# RSL15 register map
Vendor: ONSemiconductor; Series: RSL15 Series; File version: 1.0
CPU: CM33 r0p4, little endian, MPU, FPU, 3 interrupt priority bits
Registers are 32-bit, read-write, reset 0x0 unless marked. A register's access mark holds for its fields unless they carry their own. Offsets are from the block's base; [hi:lo] are bit positions; {n}, {i} and the like mark numbered series; 'fields as' and 'values as' point back to an identical list.

## BB — Baseband Controller
Base 0x40001900
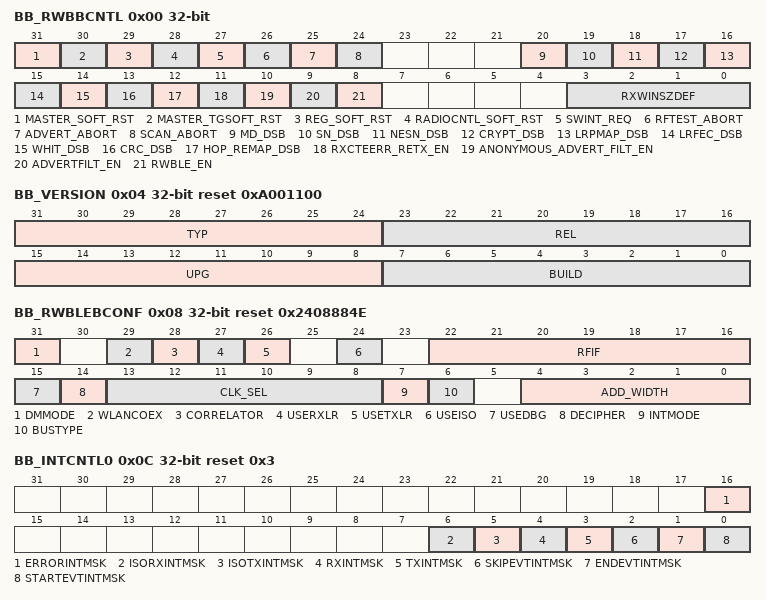
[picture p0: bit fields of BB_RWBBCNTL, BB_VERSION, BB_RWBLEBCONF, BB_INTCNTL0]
0x00 BB_RWBBCNTL — Baseband control register
  [31] MASTER_SOFT_RST — Reset the complete system except registers and timing generator
    0=No action happens if it is written with 0; 1=Resets the complete system at 0
  [30] MASTER_TGSOFT_RST — Reset the timing generator
    0=No action happens if it is written with 0; 1=Resets the timing generator at 0
  [29] REG_SOFT_RST — Reset the complete register block
    0=No action happens if it is written with 0; 1=Resets the complete register block at 0
  [28] RADIOCNTL_SOFT_RST — Reset the radio controller
    0=No action happens if it is written with 0; 1=Reset the radio controller, when written with a 1
  [27] SWINT_REQ — Force the generation of ble_sw_irq
    0=No action happens if it is written with 0; 1=When written with a 1 and proper masking is set, resets at 0
  [26] RFTEST_ABORT — Abort the current RF testing defined as per CS-FORMAT
    0=No action happens if it is written with 0; 1=Abort the current RF testing
  [25] ADVERT_ABORT — Abort the current scan window
    0=No action happens if it is written with 0; 1=Abort the current scan window
  [24] SCAN_ABORT — Abort the current advertising event
    0=No action happens if it is written with 0; 1=Abort the current advertising event
  [20] MD_DSB — Allow a single Tx/Rx exchange whatever the MD bits are
    0=Normal operation of MD bits management; 1=Allow a single Tx/Rx exchange whatever the MD bits are
  [19] SN_DSB — Disable sequence number management
    0=Normal operation of sequence number; 1=Sequence number management disabled
  [18] NESN_DSB — Disable acknowledge scheme
    0=Normal operation of acknowledge; 1=Acknowledge scheme disabled
  [17] CRYPT_DSB — Disable encryption/decryption
    0=Normal operation (encryption / decryption enabled); 1=Encryption / decryption disabled
  [16] LRPMAP_DSB — LR pattern mapper/demapper enabled (has effect only if RW_BLE_LONG_RANGE_INST is defined)
    0=Normal operation. LR Pattern Mapper/Demapper enabled; 1=LR Pattern Mapper/Demapper disabled
  [15] LRFEC_DSB — LR FEC encoder/decoder enabled (has effect only if RW_BLE_LONG_RANGE_INST is defined)
    0=Normal operation. LR FEC encoder/decoder enabled; 1=LR FEC encoder/decoder disabled
  [14] WHIT_DSB — Disable whitening
    0=Normal operation (whitening enabled); 1=Whitening disabled
  [13] CRC_DSB — Disable CRC stripping
    0=Normal operation (CRC removed from data stream); 1=CRC stripping disabled on Rx packets, CRC replaced by 0x000 in Tx
  [12] HOP_REMAP_DSB — Disable frequency hopping remapping algorithm
    0=Normal operation (requency hopping remapping algorithm enabled); 1=Frequency hopping remapping algorithm disabled
  [11] RXCTEERR_RETX_EN — Rx CTE error detection
    0=RX_CTE_ERROR_DETECTION_0 (RW-BLE Core does not reports anonymous advertiser to RW-BLE Software); 1=RX_CTE_ERROR_DETECTION_1 (RW-BLE Core reports anonymous advertisers to RW-BLE Software)
  [10] ANONYMOUS_ADVERT_FILT_EN — Anonymous extended advertising filtering enable control (operate in extended active scanner and extended passive scanner modes only, and when white list is used by device filtering policy)
    0=RW-BLE Core does not reports anonymous advertiser to RW-BLE Software; 1=RW-BLE Core reports anonymous advertisers to RW-BLE Software
  [9] ADVERTFILT_EN — Advertising channels error filtering enable control
    0=RW-BLE core reports all errors to RW-BLE software; 1=RW-BLE core reports only correctly received packet, without error to RW-BLE software
  [8] RWBLE_EN — Enable RW-BLE core exchange table pre-fetch mechanism
    0=Disable RW-BLE core exchange table pre-fetch mechanism; 1=Enable RW-BLE core exchange table pre-fetch mechanism
  [3:0] RXWINSZDEF — Default Rx window size in us (used when device is master connected or performs its second receipt)
    0=Default Rx half Window size in us for uncoded PHY, and in multiple of 2us for coded PHY
0x04 BB_VERSION ro reset 0xA001100 — BLE revision register
  [31:24] TYP — RW-BLE core type
    10=TYP_A (BLE v5.1 Madrid release)
  [23:16] REL — RW-BLE core version - major release number
  [15:8] UPG — RW-BLE core upgrade - upgrade number
    17=UPG_11
  [7:0] BUILD — RW-BLE core build - build number
0x08 BB_RWBLEBCONF ro reset 0x2408884E — Baseband configuration register (compilation options dependant)
  [31] DMMODE — RW-BLE core dual mode
    0=RW-BLE core is used as a standalone BLE device; 1=RW-BLE core is used in a dual mode device
  [29] WLANCOEX — WLAN coexistence mechanism
    0=COEX_0 (WLAN coexistence mechanism not present); 1=COEX_1 (WLAN coexistence mechanism present)
  [28] CORRELATOR — Correlator present
    0=Correlator logic is not present; 1=Correlator logic is present
  [27] USERXLR — Long range Rx present
    0=Long Range receive bit-stream logic is not present; 1=Long Range receive bit-stream logic is present
  [26] USETXLR — Long range Tx present
    0=Long Range transmit bit-stream logic is not present; 1=Long Range transmit bit-stream logic is present
  [24] USEISO — Support of isochronous channels
    0=Isochronous channel feature not supported; 1=Isochronous channel feature supported
  [22:16] RFIF — Support of the RF front-end
    1=RFIF_RIPPLE (Ripple and Thesis RF); 2=RFIF_EXT (External radio controller support); 4=RFIFCALYPSO (Calypso radio); 8=RFIF_ICYTRX_V2 (IcyTRx version 2 radio); 16=RFIF_BTIPT (BTIPT radio); 32=RFIF_AURA_SEMI (Aura semi 50xx radio); 64=RFIF_RESERVED (Reserved)
  [15] USEDBG — Diagnostic port
    0=WLAN coexistence mechanism present; 1=Diagnostic port instantiated
  [14] DECIPHER — AES deciphering present
    0=AES deciphering not present; 1=AES deciphering present
  [13:8] CLK_SEL — Operating frequency (in MHz)
    8=Default value is 8MHz
  [7] INTMODE — Interruption mode
    0=Interrupts are edge level generated, i.e. pulse; 1=Interrupts are trigger level generated, i.e. stays active at 1 till acknowledgement
  [6] BUSTYPE — Processor bus type
    0=Processor bus type: AHB bus; 1=Processor bus type: XBAR bus
  [4:0] ADD_WIDTH — Value of the RW_BLE_ADDRESS_WIDTH parameter concerted into binary
    14=EM size is 16kB
0x0C BB_INTCNTL0 reset 0x3 — Interrupts control register 0
  [16] ERRORINTMSK — Error interrupt mask
    0=Interrupt not generated; 1=Interrupt generated
  [6] ISORXINTMSK — Isochronous channel Rx interrupt mask
    0=Interrupt not reported in FIFO IRQ; 1=Interrupt reported in FIFO IRQ
  [5] ISOTXINTMSK — Isochronous channel Tx interrupt mask
    values as ISORXINTMSK
  [4] RXINTMSK — Rx interrupt mask
    values as ISORXINTMSK
  [3] TXINTMSK — Tx interrupt mask
    values as ISORXINTMSK
  [2] SKIPEVTINTMSK — Skipped event interrupt mask
    values as ISORXINTMSK
  [1] ENDEVTINTMSK — End of event interrupt mask
    values as ISORXINTMSK
  [0] STARTEVTINTMSK — Start of event interrupt mask
    values as ISORXINTMSK
0x10 BB_INTSTAT0 ro — Interrupts status register 0
  [16] ERRORINTSTAT — Error interrupt status
    0=No error interrupt; 1=An error interrupt is pending
0x14 BB_INTACK0 — Interrupts raw status register 0
  [16] ERRORINTACK — Error interrupt acknowledgement
    0=No error interrupt; 1=An error interrupt is pending
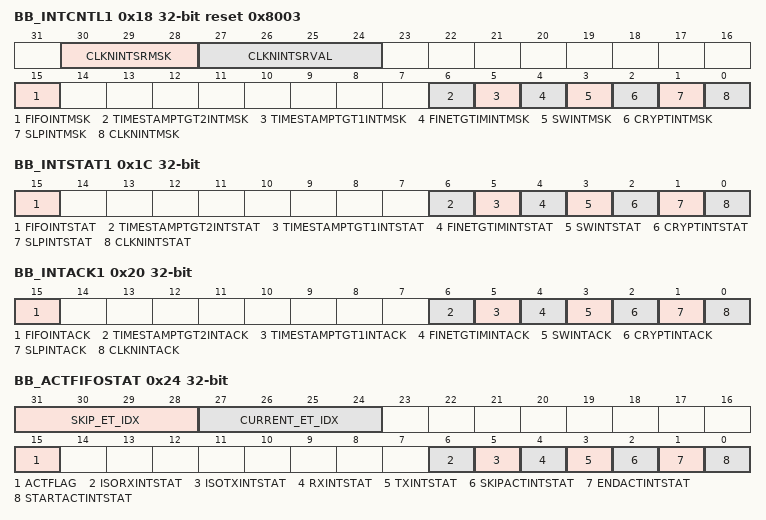
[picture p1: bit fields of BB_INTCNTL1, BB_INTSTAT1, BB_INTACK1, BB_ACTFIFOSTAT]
0x18 BB_INTCNTL1 reset 0x8003 — Interrupts control register 1
  [30:28] CLKNINTSRMSK — CLKN/half-slot interrupt sub rating mask (valid range is [0:4])
  [27:24] CLKNINTSRVAL — CLKN/half-slot interrupt sub rating value
  [15] FIFOINTMSK — FIFO interrupt mask
    0=Interrupt not generated; 1=Interrupt generated
  [6] TIMESTAMPTGT2INTMSK — Time stamp target timer 2 interrupt mask
    0=Interrupt not generated; 1=Interrupt generated
  [5] TIMESTAMPTGT1INTMSK — Time stamp target timer 1 interrupt mask
    0=Interrupt not generated; 1=Interrupt generated
  [4] FINETGTIMINTMSK — Fine target timer interrupt mask
    0=Interrupt not generated; 1=Interrupt generated
  [3] SWINTMSK — SW triggered interrupt mask
    0=Interrupt not generated; 1=Interrupt generated
  [2] CRYPTINTMSK — Encryption engine interrupt mask
    0=Interrupt not generated; 1=Interrupt generated
  [1] SLPINTMSK — Sleep mode interrupt mask
    0=Interrupt not generated; 1=Interrupt generated
  [0] CLKNINTMSK — CLKN/half slot interrupt mask
    0=Interrupt not generated; 1=Interrupt generated
0x1C BB_INTSTAT1 ro — Interrupts status register 1
  [15] FIFOINTSTAT — FIFO interrupt status
    0=No FIFO interrupt; 1=A FIFO interrupt is pending
  [6] TIMESTAMPTGT2INTSTAT — Time stamp target timer 2 interrupt status
    0=No fine target timer 2 interrupt; 1=A fine target timer 2 interrupt is pending
  [5] TIMESTAMPTGT1INTSTAT — Time stamp target timer 1 interrupt status
    0=No fine target timer 1 interrupt; 1=A fine target timer 1 interrupt is pending
  [4] FINETGTIMINTSTAT — Fine target timer interrupt status
    0=No fine target timer interrupt; 1=A fine target timer interrupt is pending
  [3] SWINTSTAT — SW triggered interrupt status
    0=No SW triggered interrupt; 1=A SW triggered interrupt is pending
  [2] CRYPTINTSTAT — Encryption engine interrupt status
    0=No encryption / decryption interrupt; 1=An encryption / decryption interrupt is pending
  [1] SLPINTSTAT — Sleep mode interrupt status
    0=No end of sleep mode interrupt; 1=An end of sleep mode interrupt is pending
  [0] CLKNINTSTAT — CLKN/half slot interrupt status
    0=No half slot interrupt; 1=A half slot interrupt is pending
0x20 BB_INTACK1 — Interrupts acknowledgement register 1
  [15] FIFOINTACK — FIFO interrupt acknowledgement
    0=FIFOINTACK_0; 1=Acknowledge the FIFO interrupt
  [6] TIMESTAMPTGT2INTACK — Time stamp target timer 2 interrupt acknowledgement
    0=TIMESTAMPTGT2INTACK_0; 1=Acknowledge the time stamp target timer 2 interrupt
  [5] TIMESTAMPTGT1INTACK — Time stamp target timer 1 interrupt acknowledgement
    0=TIMESTAMPTGT1INTACK_0; 1=Acknowledge the time stamp target timer 1 interrupt
  [4] FINETGTIMINTACK — Fine target timer interrupt acknowledgement
    0=FINETGTIMINTACK_0; 1=Acknowledge the fine timer interrupt
  [3] SWINTACK — SW triggered interrupt acknowledgement
    0=SWINTACK_0; 1=Acknowledge the SW triggered timer interrupt
  [2] CRYPTINTACK — Encryption engine interrupt acknowledgement
    0=CRYPTINTACK_0; 1=Acknowledge the encryption timer interrupt
  [1] SLPINTACK — Sleep mode interrupt acknowledgement
    0=SLPINTACK_0; 1=Acknowledge the end of sleep interrupt
  [0] CLKNINTACK — CLKN/half slot interrupt acknowledgement
    0=CLKNINTACK_0; 1=Acknowledge the half slot interrupt
0x24 BB_ACTFIFOSTAT ro — Actif FIFO status register
  [31:28] SKIP_ET_IDX — Exchange table entry index of the reported skipped event (valid when SKIPACTINTSTAT is set)
  [27:24] CURRENT_ET_IDX — Exchange table entry index of the reported current event (valid for any set reported interrupt except SKIPACTINTSTAT)
  [15] ACTFLAG — Forced to 1 in BLE
  [6] ISORXINTSTAT — Isochronous channel Rx interrupt status
    0=No isochronous channel Rx interrupt; 1=An isochronous channel Rx interrupt is pending
  [5] ISOTXINTSTAT — Isochronous channel Tx interrupt status
    0=No isochronous channel Tx interrupt; 1=An isochronous channel Tx interrupt is pending
  [4] RXINTSTAT — Rx interrupt status
    0=No Rx interrupt; 1=An Rx interrupt is pending
  [3] TXINTSTAT — Tx interrupt status
    0=No Tx interrupt; 1=A Tx interrupt is pending
  [2] SKIPACTINTSTAT — Skipped event interrupt status
    0=No skipped event interrupt; 1=A skipped event interrupt is pending
  [1] ENDACTINTSTAT — End of event interrupt status
    0=No end of event interrupt; 1=An end of event interrupt is pending
  [0] STARTACTINTSTAT — Start of event interrupt status
    0=No start of event interrupt; 1=A start of event interrupt is pending
0x28 BB_CURRENTRXDESCPTR — Rx descriptor pointer register
  [13:0] CURRENTRXDESCPTR — Rx descriptor pointer that determines the starting point of the receive buffer chained list
0x2C BB_ETPR — Rx descriptor pointer register
  [13:0] ETPTR — Exchange table pointer that determines the starting point of the exchange table
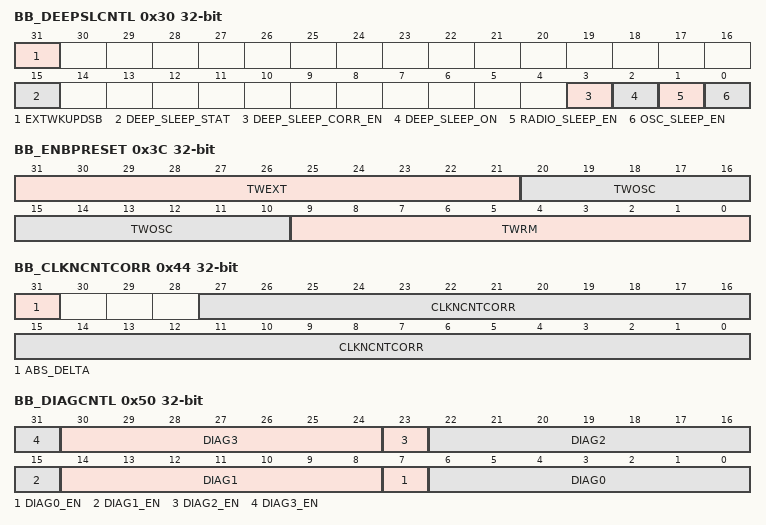
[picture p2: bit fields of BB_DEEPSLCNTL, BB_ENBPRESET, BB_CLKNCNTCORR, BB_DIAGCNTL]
0x30 BB_DEEPSLCNTL — Deep sleep control register
  [31] EXTWKUPDSB — External wake-up disable
    0=RW-BLE core can be woken by external wake-up; 1=RW-BLE core cannot be woken up by external wake-up
  [15] DEEP_SLEEP_STAT ro — Indicator of current deep sleep clock mux status
    0=RW-BLE core is not yet in deep sleep mode; 1=RW-BLE core is in deep sleep mode (only low_power_clk is running)
  [3] DEEP_SLEEP_CORR_EN — Half slot counter integer and fractional part correction (apply when system has been woken-up from deep sleep mode)
    0=No action happens if it is written with 0; 1=Enables fine counter and base time counter when written
  [2] DEEP_SLEEP_ON — RW-BLE core power mode control
    0=RW-BLE core in normal active mode; 1=Request RW-BLE core to switch in deep sleep mode
  [1] RADIO_SLEEP_EN — Control the radio module
    0=Radio stands in normal active mode; 1=Allow to disable radio
  [0] OSC_SLEEP_EN — Control the RF high frequency crystal oscillator
    0=High frequency crystal oscillator stands in normal active mode; 1=Allow to disable high frequency crystal oscillator
0x34 BB_DEEPSLWKUP — Deep sleep wakeup register
  [31:0] DEEPSLTIME — Determine the time in low_power_clk clock cycles to spend in deep sleep mode before waking-up the device
0x38 BB_DEEPSLSTAT ro — Deep sleep status register
  [31:0] DEEPSLDUR — Actual duration of the last deep sleep phase measured in low_power_clk clock cycle
    0=DEEPSLDUR is set to zero at the beginning of the deep sleep phase, and is incremented at each low_power_clk clock cycle until the end of the deep sleep phase
0x3C BB_ENBPRESET — Stabilization times
  [31:21] TWEXT — Time in low power oscillator cycles allowed for stabilization of the high frequency oscillator following an external wake-up request (signal wakeup_req)
  [20:10] TWOSC — Time in low power oscillator cycles allowed for stabilization of the high frequency oscillator when the deep-sleep mode has been left due to sleep-timer expiry (DEEPSLWKUP-DEEPSLTIME])
  [9:0] TWRM — Time in low power oscillator cycles allowed for the radio module to leave low-power mode
0x40 BB_FINECNTCORR — Fine timer correction register
  [9:0] FINECNTCORR — Phase correction value for the 312.5us reference counter (i.e. fine counter) in half us
0x44 BB_CLKNCNTCORR — Slot clock correction register
  [31] ABS_DELTA — Determine whether CLKNCNTCORR is an absolute correction or a signed "delta" increment correction
    0=Absolute correction; 1=Signed "delta" increment correction
  [27:0] CLKNCNTCORR — CLKN counter correction value
    0=CLKN Counter correction value
0x50 BB_DIAGCNTL — Diagnostic ports control register
  [8n+7] DIAG{n}_EN (n=0..3) — Enable diagnostic port {n} output
    0=Disable diagnostic port {n} output. All outputs are set to 0x0.; 1=Enable diagnostic port {n} output
  [30:24] DIAG3 — Selection of the outputs that must be driven to the diagnostic port 3
    0=DIAG3_0
  [22:16] DIAG2 — Selection of the outputs that must be driven to the diagnostic port 2
    0=DIAG2_0
  [14:8] DIAG1 — Selection of the outputs that must be driven to the diagnostic port 1
    0=DIAG1_0
  [6:0] DIAG0 — Selection of the outputs that must be driven to the diagnostic port 1
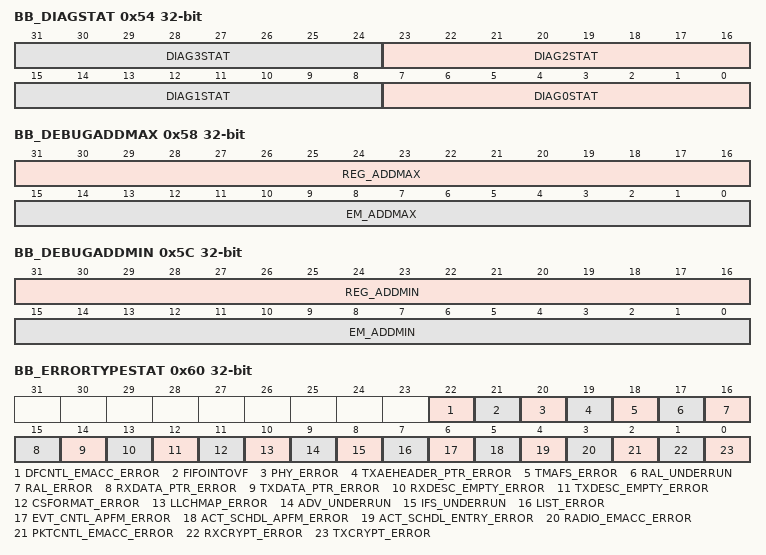
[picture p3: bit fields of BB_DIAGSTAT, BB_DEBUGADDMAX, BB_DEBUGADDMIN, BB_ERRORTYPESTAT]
0x54 BB_DIAGSTAT ro — Diagnostic ports status register
  [8n+7:8n] DIAG{n}STAT (n=0..3) — Directly connected to ble_dbg{n}[7:0] output (debug use only)
    0=DIAG{n}STAT_0
0x58 BB_DEBUGADDMAX — Diagnostic ports upper limit
  [31:16] REG_ADDMAX — Upper limit for the register zone indicated by the reg_inzone flag
  [15:0] EM_ADDMAX — Upper limit for the exchange memory zone indicated by the em_inzone flag
0x5C BB_DEBUGADDMIN — Diagnostic ports lower limit
  [31:16] REG_ADDMIN — Lower limit for the register zone indicated by the reg_inzone flag
  [15:0] EM_ADDMIN — Lower limit for the exchange memory zone indicated by the em_inzone flag
0x60 BB_ERRORTYPESTAT ro — Diagnostic ports errors register
  [all] fields
    0=No error; 1=Error occurred
  [22] DFCNTL_EMACC_ERROR — Indicate that direction finding controller has an EM Access error (happen when exchange memory accesses are not served in time and data are corrupted)
  [21] FIFOINTOVF — Indicate that the FIFO IRQ is overflowed
  [20] PHY_ERROR — Indicate that the programmed CS-AUX/TX/RX-RATE fields are not matching the RADIOCNTL2-PHYMSK fields indicating which PHY the radio is currently supporting
  [19] TXAEHEADER_PTR_ERROR — Indicate Tx pointer to the extended advertising packet that has to be sent is null, while the extended header length is not null and the packet to be sent is an extended advertising packet
  [18] TMAFS_ERROR — Indicate T_MAFS is smaller than 300us in between a transmitted advertising packet containing an AuxPtr field and its chained packet (this comes from bad settings of Aux_Offset and/or Offset_Unit values)
  [17] RAL_UNDERRUN — Indicate resolving address list engine under run issue (happen when RAL List parsing not finished on time)
  [16] RAL_ERROR — Indicate resolving address list engine faced a bad setting
  [15] RXDATA_PTR_ERROR — Indicate whether Rx data buffer pointer value programmed is null (major failure)
  [14] TXDATA_PTR_ERROR — Indicate whether Tx data buffer pointer value programmed is null during advertising/scanning/initiating events, or during master/slave connections with non-null packet length (major failure)
  [13] RXDESC_EMPTY_ERROR — Indicate whether Rx descriptor pointer value programmed in register is null (major failure)
  [12] TXDESC_EMPTY_ERROR — Indicate whether Tx descriptor pointer value programmed in control structure is null during advertising/scanning/initiating events (major failure)
  [11] CSFORMAT_ERROR — Indicate whether CS-FORMAT has been programmed with an invalid value (major failure)
  [10] LLCHMAP_ERROR — Indicate link layer channel map error (happen when actual number of CS-LLCHMAP bit set to one is different from CS-NBCHGOOD at the beginning of frequency hopping process)
  [9] ADV_UNDERRUN — Indicate advertising interval under run
  [8] IFS_UNDERRUN — Indicate inter frame space under run (occur if IFS time is not enough to update and read control structure/descriptors, and/or white list parsing is not finished and/or decryption time is too long to be finished on time)
  [7] LIST_ERROR — Indicate a software programming issue (white list or periodic advertiser list or ADI list search request with empty list, or null base pointer)
  [6] EVT_CNTL_APFM_ERROR — Indicate anticipated pre-fetch mechanism error (happen when 2 consecutive events are programmed, and when the first event is not completely finished while second pre-fetch instant is reached)
  [5] ACT_SCHDL_APFM_ERROR — Indicate anticipated pre-fetch mechanism error (happen when 2 consecutive events are programmed, and when the first event is not completely finished while second pre-fetch instant is reached)
  [4] ACT_SCHDL_ENTRY_ERROR — Indicate activity scheduler faced Invalid timing programing on two consecutive ET entries
  [3] RADIO_EMACC_ERROR — Indicate radio controller exchange memory access error (happen when exchange memory accesses are not served in time and data are corrupted)
  [2] PKTCNTL_EMACC_ERROR — Indicate packet controller exchange memory access error (happen when exchange memory accesses are not served in time and Tx/Rx data are corrupted)
  [1] RXCRYPT_ERROR — Indicate real time decryption error (happen when AES-CCM decryption is too slow compared to packet controller requests)
  [0] TXCRYPT_ERROR — Indicate real time encryption error (happen when AES-CCM encryption is too slow compared to packet controller requests)
0x64 BB_SWPROFILING — Software profiling register
  [31:0] SWPROF — Software profiling register (used by RW-BLE software for profiling purpose)
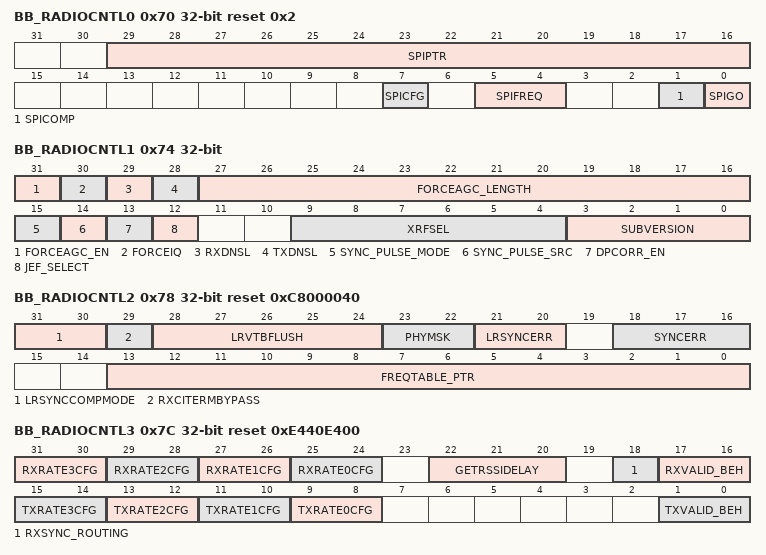
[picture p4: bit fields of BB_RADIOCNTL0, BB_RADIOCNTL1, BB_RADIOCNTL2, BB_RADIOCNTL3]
0x70 BB_RADIOCNTL0 reset 0x2 — Principal control register for the radio interface
  [29:16] SPIPTR — Pointer to the buffer containing data to be transferred to or received from the SPI port
    0=SPI pointer
  [7] SPICFG — SPI configuration/used for SW-driven access and SPI structure interpretation (interpretation is radio dependent)
  [5:4] SPIFREQ — SPI clock frequency
    0=SPI clock is master1_gclk / 2; 1=NA for IcyTRX; 2=NA for IcyTRX; 3=NA for IcyTRX
  [1] SPICOMP ro — SPI transfer status
    0=Indicates SPI transfer in progress; 1=Indicates SPI transfer is completed. RW-BLE core is ready to start a new transfer
  [0] SPIGO — Start SPI transfer when writing a 1
    0=SPIGO_0; 1=Triggers the SPI transfer
0x74 BB_RADIOCNTL1 — Second control register for the radio interface
  [31] FORCEAGC_EN — Control AGC force mode based onto FORCEAGC_LENGTH value
    0=Disable; 1=Enable
  [30] FORCEIQ — Control modulation mode in between FM and I&Q
    0=FORCEBLEIQ_0 (FM modulation mode); 1=FORCEBLEIQ_1 (I&Q modulation mode)
  [29] RXDNSL — Do not send length (over SPI) during Rx operation
    0=Normal operations; 1=Prevent from sending valid reception length indication to the RF over SPI
  [28] TXDNSL — Do not send length (over SPI) during Tx operation
    0=Normal operations; 1=Prevent from sending valid transmit length indication to the RF over SPI
  [27:16] FORCEAGC_LENGTH — Control ATLAS/Ripple AGC force mode based on radioCNTL2-FORCEAGC_LENGTH value
  [15] SYNC_PULSE_MODE — Define whether the SYNC_P pulse is generated as pulse or level
    0=SYNC_P generated as pulse; 1=SYNC_P generated as level
  [14] SYNC_PULSE_SRC — Define whether access address synchronization detection is generated internally or comes from the radio
    0=Internal detection; 1=External detection
  [13] DPCORR_EN — Enable the use of delayed DC compensated data path in radio correlator block
    0=Disable; 1=Enable
  [12] JEF_SELECT — Select jitter elimination FIFO
  [9:4] XRFSEL — Extended radio selection field
    0=NONE (No radio selected); 1=RIPPLE (Ripple radio (BT4.0)); 2=EXTERNAL (External radio controller); 4=ICYTRX_V2 (ICYTRX radio (BLE)); 5=BTIPT (BTIPT Radio Controller)
  [3:0] SUBVERSION — CSEM RF sub-version selection
    0=GCS2_LR (IcyTRx GCS2 withLong Range (BLE 5.0)); 1=GCS3 (IcyTRx GCS3 (BLE 5.1))
0x78 BB_RADIOCNTL2 reset 0xC8000040 — Third control register for the radio interface
  [31:30] LRSYNCCOMPMODE — Long-range synchronization compensation operating mode
    3=Bit 0 controls 125kbps LR packet part using synchro tracking and Bit 1 controls 500kbps LR packet part using synchro tracking
  [29] RXCITERMBYPASS — Long-range CI bit[1] and TERM1 bypass mode (allow to receive only CI bit 0 and then wait for Rx payload directly)
  [28:24] LRVTBFLUSH — Indicate long range Viterbi flush instant (this value corresponds to the Viterbi trace back depth used in the selected design, hence corresponding to the number of remaining samples flush out just before the end of the packet)
  [23:22] PHYMSK — Indicate selected radio PHY support capabilities (in addition to 1Mbps that is mandatory)
    0=Bit 0 indicates 2Mbps support when set. Bit 1 indicates Coded HPY support when set
  [21:20] LRSYNCERR — Number of errors allowed during long range Rx stream detection (when performed internally)
  [18:16] SYNCERR — Indicate the maximum number of errors allowed to recognize the synchronization word
    0=Has to be set to 0x0 for normal operations
  [13:0] FREQTABLE_PTR — Frequency table pointer
0x7C BB_RADIOCNTL3 reset 0xE440E400 — Fourth control register for the radio interface
  [31:30] RXRATE3CFG — Rate out programmable value in Rx when CS-RXRATE is set to 0x3 (i.e 500kbps Long range)
    3=RXRATE3CFG_3
  [29:28] RXRATE2CFG — Rate out programmable value in Rx when CS-RXRATE is set to 0x2 (i.e 125kbps Long range)
    2=RXRATE3CFG_2
  [27:26] RXRATE1CFG — Rate out programmable value in Rx when CS-RXRATE is set to 0x1 (i.e 2Mbps)
    1=RXRATE3CFG_1
  [25:24] RXRATE0CFG — Rate out programmable value in Rx when CS-RXRATE is set to 0x0 (i.e 1Mbps)
    0=RXRATE3CFG_0
  [22:20] GETRSSIDELAY — Delay to read RSSI after an RSSI read request
  [18] RXSYNC_ROUTING — Access address detection information routing
    0=Uses radio_in[16] (i.e sync_p); 1=Uses first radio_in[3] edge (Rx Valid)
  [17:16] RXVALID_BEH — Define radio_in[3] expected behavior
    0=Rx data aligned on radio_in[3] rising edges; 1=Rx data aligned on radio_in[3] falling edges; 2=Rx data aligned on radio_in[3] edges (toggle mode); 3=NA
  [15:14] TXRATE3CFG — Rate out programmable value in Tx when CS-TX/AUX-RATE is set to 0x3 (i.e 500kbps Long range)
    3=TXRATE3CFG_3
  [13:12] TXRATE2CFG — Rate out programmable value in Tx when CS-TX/AUX-RATE is set to 0x2 (i.e 125kbps Long range)
    2=TXRATE3CFG_2
  [11:10] TXRATE1CFG — Rate out programmable value in Tx when CS-TX/AUX-RATE is set to 0x1 (i.e 2Mbps)
    1=TXRATE3CFG_1
  [9:8] TXRATE0CFG — Rate out programmable value in Tx when CS-TX/AUX-RATE is set to 0x0 (i.e 1Mbps)
    0=TXRATE3CFG_0
  [1:0] TXVALID_BEH — Define radio_out [3] expected behavior
    0=Tx data aligned on radio_out[3] rising edges; 1=Tx data aligned on radio_out[3] falling edges; 2=Tx data aligned on radio_out[3] edges (toggle mode); 3=NA
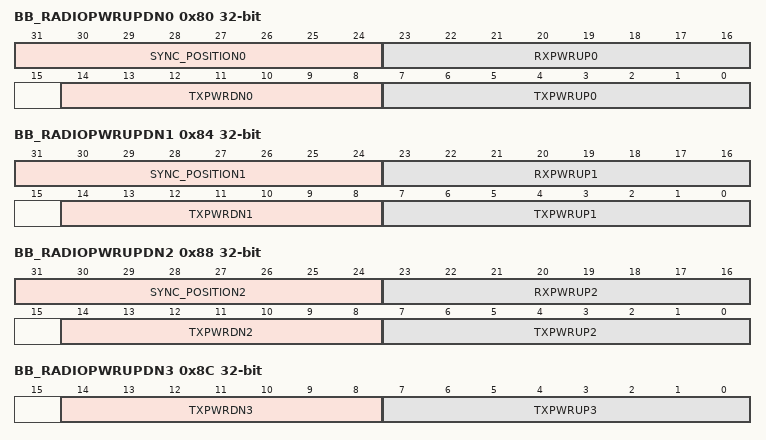
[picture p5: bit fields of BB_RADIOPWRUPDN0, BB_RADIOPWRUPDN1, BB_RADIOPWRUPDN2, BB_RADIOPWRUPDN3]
0x80 BB_RADIOPWRUPDN0 — Principal control register for the radio interface power up/down delays
  [31:24] SYNC_POSITION0 — Access address detection pulse/level position for uncoded PHY at 1Mbps
  [23:16] RXPWRUP0 — Radio Rx power up (in us) for uncoded PHY at 1Mbps
  [14:8] TXPWRDN0 — Radio Tx power down (in us) for uncoded PHY at 1Mbps
  [7:0] TXPWRUP0 — Radio Tx power up (in us) for uncoded PHY at 1Mbps
0x84 BB_RADIOPWRUPDN1 — Second control register for the radio interface power up/down delays
  [31:24] SYNC_POSITION1 — Access address detection pulse/level position for uncoded PHY at 2Mbps
    0=SYNC_POSITION1_0
  [23:16] RXPWRUP1 — Radio Rx power up (in us) for uncoded PHY at 2Mbps
    0=RXPWRUP1_0
  [14:8] TXPWRDN1 — Radio Tx power down (in us) for uncoded PHY at 2Mbps
    0=TXPWRDN1_0
  [7:0] TXPWRUP1 — Radio Tx power up (in us) for uncoded PHY at 2Mbps
    0=TXPWRUP1_0
0x88 BB_RADIOPWRUPDN2 — Third control register for the radio interface power up/down delays (only when LR is instantiated)
  [31:24] SYNC_POSITION2 — Access address detection pulse/level position for coded PHY at 125kbps
    0=SYNC_POSITION2_0
  [23:16] RXPWRUP2 — Radio Rx power up (in us) for coded PHY at 125kbps
    0=RXPWRUP2_0
  [14:8] TXPWRDN2 — Radio Tx power down (in us) for coded PHY at 125kbps
    0=TXPWRDN2_0
  [7:0] TXPWRUP2 — Radio Tx power up (in us) for coded PHY at 125kbps
    0=TXPWRUP2_0
0x8C BB_RADIOPWRUPDN3 — Fourth control register for the radio interface power up/down delays (only when LR is instantiated)
  [14:8] TXPWRDN3 — Radio Tx power down (in us) for coded PHY at 500kbps
    0=TXPWRDN3_0
  [7:0] TXPWRUP3 — Radio Tx power up for (in us) PHY at 500kbps
    0=TXPWRUP3_0
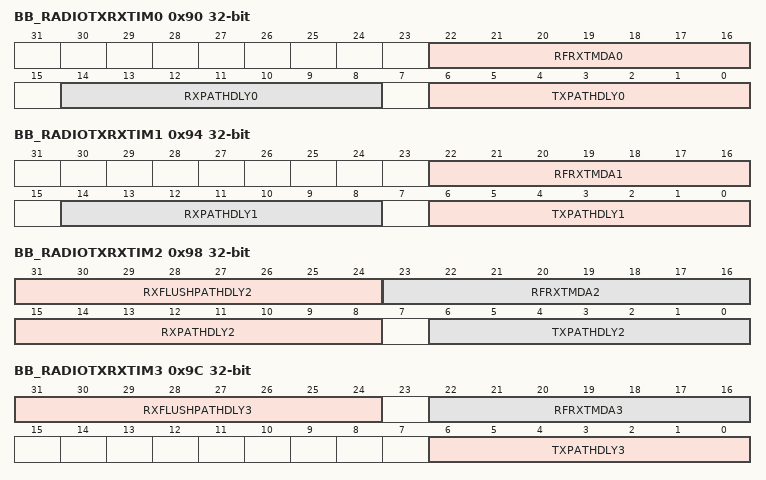
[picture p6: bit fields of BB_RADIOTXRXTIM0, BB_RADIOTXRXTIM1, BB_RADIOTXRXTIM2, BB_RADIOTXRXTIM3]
0x90 BB_RADIOTXRXTIM0 — Principal control register for the radio interface timing compensation delays
  [22:16] RFRXTMDA0 — RF Rx test mode delay adjustment for uncoded PHY at 1Mbps
  [14:8] RXPATHDLY0 — Rx path delay (in us) for uncoded PHY at 1Mbps
  [6:0] TXPATHDLY0 — Rx path delay (in us) for uncoded PHY at 1Mbps
0x94 BB_RADIOTXRXTIM1 — Second control register for the radio interface timing compensation delays
  [22:16] RFRXTMDA1 — RF Rx test mode delay adjustment for uncoded PHY at 2Mbps
    0=RFRXTMDA1_0
  [14:8] RXPATHDLY1 — Rx path delay (in us) for uncoded PHY at 2Mbps
    0=RXPATHDLY1_0
  [6:0] TXPATHDLY1 — Rx path delay (in us) for uncoded PHY at 2Mbps
    0=TXPATHDLY1_0
0x98 BB_RADIOTXRXTIM2 — Third control register for the radio interface timing compensation delays (only when LR is instantiated)
  [31:24] RXFLUSHPATHDLY2 — Rx path delay (in us) for coded PHY at 125kbps
    0=RXFLUSHPATHDLY2_0
  [23:16] RFRXTMDA2 — RF Rx test mode delay adjustment for uncoded PHY at 125kbps
    0=RFRXTMDA2_0
  [15:8] RXPATHDLY2 — Rx path delay (in us) for uncoded PHY at 125kbps
    0=RXPATHDLY2_0
  [6:0] TXPATHDLY2 — Rx path delay (in us) for uncoded PHY at 125kbps
    0=TXPATHDLY2_0
0x9C BB_RADIOTXRXTIM3 — Fourth control register for the radio interface timing compensation delays (only when LR is instantiated)
  [31:24] RXFLUSHPATHDLY3 — Rx path delay (in us) for coded PHY at 500kbps
    0=RXFLUSHPATHDLY3_0
  [22:16] RFRXTMDA3 — RF Rx test mode delay adjustment for coded PHY at 500kbps
    0=RFRXTMDA3_0
  [6:0] TXPATHDLY3 — Rx path delay (in us) for coded PHY at 500kbps
    0=TXPATHDLY3_0
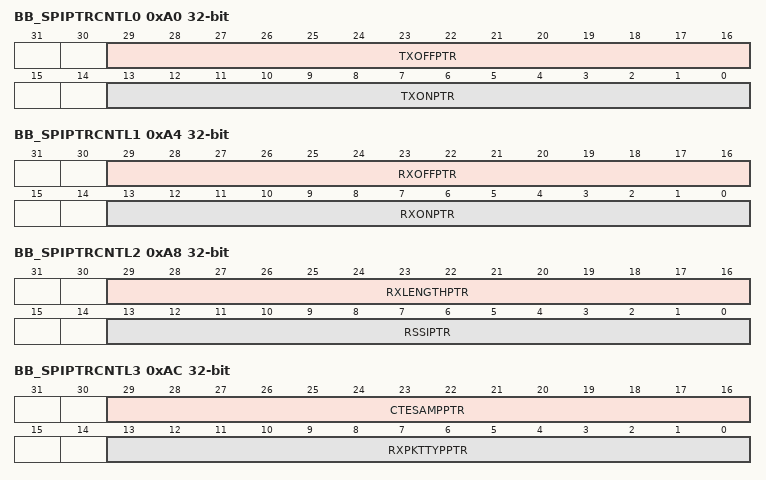
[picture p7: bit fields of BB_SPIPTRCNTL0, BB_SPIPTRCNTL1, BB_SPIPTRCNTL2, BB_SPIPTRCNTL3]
0xA0 BB_SPIPTRCNTL0 — First control register for the radio interface SPI pointers
  [29:16] TXOFFPTR — Pointer to the TxOFF sequence address section
  [13:0] TXONPTR — Pointer to the TxON sequence address section
0xA4 BB_SPIPTRCNTL1 — Second control register for the radio interface SPI pointers
  [29:16] RXOFFPTR — Pointer to the RxOFF sequence address section
  [13:0] RXONPTR — Pointer to the RxON sequence address section
0xA8 BB_SPIPTRCNTL2 — Third control register for the radio interface SPI pointers
  [29:16] RXLENGTHPTR — Pointer to the received length write sequence address section
  [13:0] RSSIPTR — Pointer to the RSSI read sequence address section
0xAC BB_SPIPTRCNTL3 — Fourth control register for the radio interface SPI pointers
  [29:16] CTESAMPPTR — Pointer to the CTE sampling indication sequence address section
  [13:0] RXPKTTYPPTR — Pointer to the received packet type indication sequence address section
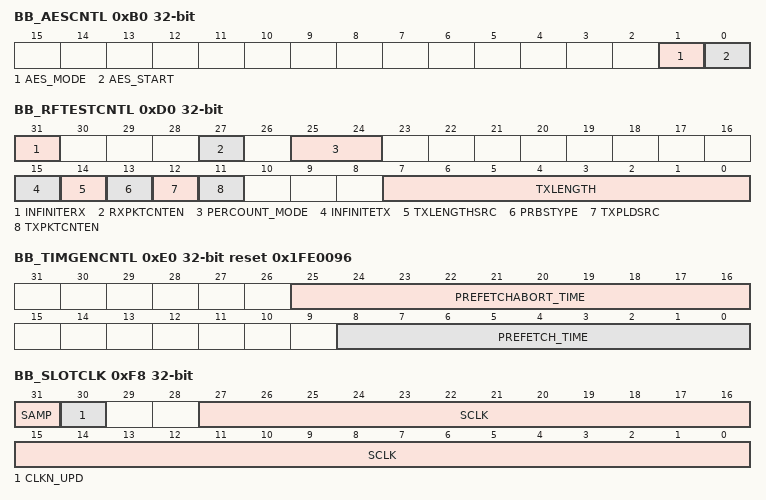
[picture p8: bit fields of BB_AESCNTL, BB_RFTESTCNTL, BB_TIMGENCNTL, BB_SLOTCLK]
0xB0 BB_AESCNTL — AES-128 ciphering control register
  [1] AES_MODE — Cipher mode control
    0=Cipher mode; 1=Decipher mode
  [0] AES_START — Start AES-128 ciphering/deciphering process
    0=AES_START_0; 1=Starts AES-128 ciphering/deciphering process (the bit is reset once the process is finished)
0xB4 BB_AESKEY31_0 — AES encryption 128-bit key register (bits 31:0)
  [31:0] AESKEY31_0 — AES encryption 128-bit key (bits 31 down to 0)
    0=AESKEY31_0_0
0xB8 BB_AESKEY63_32 — AES encryption 128-bit key register (bits 63:32)
  [31:0] AESKEY63_32 — AES encryption 128-bit key (bits 63 down to 32)
    0=AESKEY63_32_0
0xBC BB_AESKEY95_64 — AES encryption 128-bit key register (bits 95:64)
  [31:0] AESKEY95_64 — AES encryption 128-bit key (bits 95 down to 64)
    0=AESKEY95_64_0
0xC0 BB_AESKEY127_96 — AES encryption 128-bit key register (bits 127:96)
  [31:0] AESKEY127_96 — AES encryption 128-bit key (bits 127 down to 96)
    0=AESKEY127_96_0
0xC4 BB_AESPTR — AES memory zone pointer
  [13:0] AESPTR — Pointer to the memory zone where the block to cipher/decipher using AES-128 is stored
0xC8 BB_TXMICVAL ro — AES-CCM plain MIC value register in Tx
  [31:0] TXMICVAL — AES-CCM plain MIC value (valid on when MIC has been calculated in Tx)
0xCC BB_RXMICVAL ro — AES-CCM plain MIC value register in Rx
  [31:0] RXMICVAL — AES-CCM plain MIC value (valid on once MIC has been extracted from Rx packet)
0xD0 BB_RFTESTCNTL — RF testing and regulatory body support register
  [31] INFINITERX — Applicable in RF test mode only
    0=Normal mode of operation; 1=Infinite Rx window
  [27] RXPKTCNTEN — Applicable in RF test mode only
    0=Rx packet count disabled
  [25:24] PERCOUNT_MODE — Applicable in RF direct Rx test mode only, and when RXPKTCNTEN equals to 1
    0=Counts number of correctly received packets (no error); 1=Counts number of Access Address error detection only; 2=Counts number of CRC Error detection only (or any error leading to CRC error, such as length error or Rx time error); 3=Counts Reception Error detected
  [15] INFINITETX — Applicable in RF test mode only
    0=Normal mode of operation; 1=Infinite Tx packet / Normal start of a packet but endless payload
  [14] TXLENGTHSRC — Applicable only in Tx/Rx RF test mode
    0=Normal mode of operation: TxDESC-TXADVLEN controls the Tx packet payload size; 1=Uses RFTESTCTRL-TXLENGTH packet length (can support up to 512 bytes transmit)
  [13] PRBSTYPE — Applicable only in Tx/Rx RF test mode
    0=Tx packet payload are PRBS9 type; 1=Tx packet payload are PRBS15 type
  [12] TXPLDSRC — Applicable only in Tx/Rx RF test mode
    0=Tx packet payload source is the control structure; 1=Tx packet payload are PRBS generator
  [11] TXPKTCNTEN — Applicable in RF test mode only
    0=Tx packet count disabled; 1=Tx packet count enabled, and reported in CS-TXCCMPKTCNT and RFTESTTXSTAT-TXPKTCNT on RF abort command
  [7:0] TXLENGTH — Tx packet length in number of byte
0xD4 BB_RFTESTTXSTAT ro — Number of transmitted packet during test modes
  [31:0] TXPKTCNT — Report number of transmitted packet during test modes
0xD8 BB_RFTESTRXSTAT ro — Number of correctly received packet during test modes
  [31:0] RXPKTCNT — Report number of correctly received packet during test modes
0xE0 BB_TIMGENCNTL reset 0x1FE0096 — Timing generator control register
  [25:16] PREFETCHABORT_TIME — Define the instant in us at which immediate abort is required after anticipated pre-fetch abort
    0x1FE=PREFETCHABORT_TIME_254
  [8:0] PREFETCH_TIME — Define exchange table pre-fetch instant in us
0xE4 BB_FINETIMTGT — Fine timer control register
  [27:0] FINETARGET — Fine timer target value on which a ble_finetgtim_irq must be generated (this timer has a precision of 312.5us and interrupt is generated only when FINETARGET = CLKN)
0xE8 BB_CLKNTGT1 — CLKN target value 1
  [27:0] CLKNTGT1 — This timer has a precision of 312.5us (interrupt is generated only when CLKNTGT = CLKN and HMICROSECTGT = FINECNT)
    0=CLKNTGT1_0
0xEC BB_HMICROSECTGT1 — Half microsecond target value 1
  [9:0] HMICROSECTGT1 — This timer has a precision of 0.5us (interrupt is generated only when CLKNTGT = CLKN and HMICROSECTGT = FINECNT)
    0=HMICROSECTGT1_0
0xF0 BB_CLKNTGT2 — CLKN target value 2
  [27:0] CLKNTGT2 — This timer has a precision of 312.5us (interrupt is generated only when CLKNTGT = CLKN and HMICROSECTGT = FINECNT)
    0=CLKNTGT2_0
0xF4 BB_HMICROSECTGT2 — Half microsecond target value 2
  [9:0] HMICROSECTGT2 — This timer has a precision of 0.5us (interrupt is generated only when CLKNTGT = CLKN and HMICROSECTGT = FINECNT)
    0=HMICROSECTGT2_0
0xF8 BB_SLOTCLK — Value of the 312.5us CLKN counter
  [31] SAMP — Sample the CLKN counter value in SCLK register field
    0=No action happens if it is written with 0; 1=Sample the CLKN Counter value in SCLK register field
  [30] CLKN_UPD — Update CLKN counter
    0=No action happens if it is written with 0; 1=Update CLKN counter
  [27:0] SCLK — Value of the 312.5us CLKN counter
0xFC BB_FINETIMECNT ro — Value of the current half us fine time reference counter
  [9:0] FINECNT — This timer has a precision of 0.5us (interrupt is generated only when CLKNTGT = CLKN and HMICROSECTGT = FINECNT)
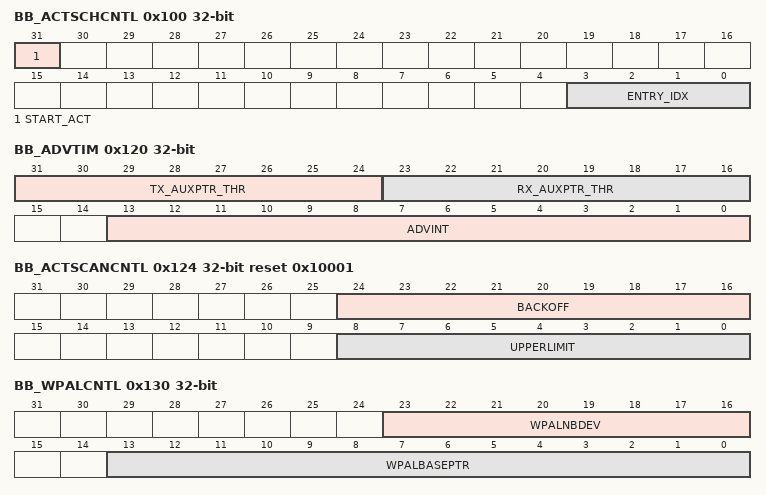
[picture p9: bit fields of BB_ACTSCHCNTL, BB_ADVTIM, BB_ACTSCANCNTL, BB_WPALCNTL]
0x100 BB_ACTSCHCNTL — Value of the 312.5us CLKN counter
  [31] START_ACT — Request the RW-BLE core to start an event
    0=No action happens if it is written with 0; 1=Request the RW-BLE Core to start an event
  [3:0] ENTRY_IDX — Indicate the activity scheduler entry index which has to be used when START_ACT is set
0x104 BB_STARTEVTCLKNTS ro — Value of the CLKN counter when ble_start_int is generated
  [27:0] STARTEVTCLKNTS
0x108 BB_STARTEVTFINECNTTS ro — Value of the fine counter when ble_start_int is generated
  [9:0] STARTEVTFINECNTTS
0x10C BB_ENDEVTCLKNTS ro — Value of the CLKN counter when ble_end_int is generated
  [27:0] ENDEVTCLKNTS
0x110 BB_ENDEVTFINECNTTS ro — Value of the fine counter when ble_end_int is generated
  [9:0] ENDEVTFINECNTTS
0x114 BB_SKIPEVTCLKNTS ro — Value of the CLKN counter when ble_skip_int is generated
  [27:0] SKIPEVTCLKNTS
0x118 BB_SKIPEVTFINECNTTS ro — Value of the fine counter when ble_skip_int is generated
  [9:0] SKIPEVTFINECNTTS
0x120 BB_ADVTIM — Delay information register handling advertising event timers
  [31:24] TX_AUXPTR_THR — Extended advertising AuxPtr threshold value in Tx (granularity 16us)
  [23:16] RX_AUXPTR_THR — Extended advertising AuxPtr threshold value in Rx (granularity 16us)
  [13:0] ADVINT — Advertising packet interval defining the time interval in between two ADV_xxx packet sent (value in us)
0x124 BB_ACTSCANCNTL reset 0x10001 — Active scan mode control register
  [24:16] BACKOFF — Active scan mode back-off counter initialization value
  [8:0] UPPERLIMIT — Active scan mode upper limit counter value
0x130 BB_WPALCNTL — Devices in white list
  [23:16] WPALNBDEV — Number of devices in the white list
  [13:0] WPALBASEPTR — Base address pointer of the white list
0x134 BB_WPALCURRENPTR — Current pointer in use for the White List
  [13:0] WPALCURRENPTR — Current pointer in use for the white list
0x138 BB_SEARCH_TIMEOUT reset 0x10 — RAL and List Search engines timeout delay in us
  [5:0] SEARCH_TIMEOUT — RAL and list search engines timeout delay in us
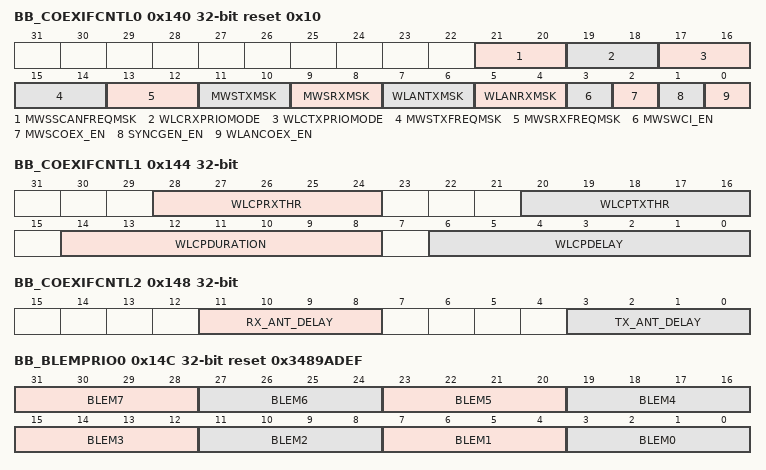
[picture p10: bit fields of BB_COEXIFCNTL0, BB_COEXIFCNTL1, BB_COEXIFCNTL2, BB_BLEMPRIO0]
0x140 BB_COEXIFCNTL0 reset 0x10 — WLAN coexistence control register 0
  [21:20] MWSSCANFREQMSK — Determine how mws_scan_frequency impacts BLE Tx and Rx
    0=mws_scan_frequency has no impact; 1=mws_scan_frequency can stop BLE Tx, no impact on BLE Rx; 2=mws_scan_frequency can stop BLE Rx, no impact on BLE Tx; 3=mws_scan_frequency can stop both BLE Tx and BLE Rx
  [19:18] WLCRXPRIOMODE — Define BLE packet ble_rx mode behavior
    0=Rx indication excluding Rx power up delay (starts when correlator is enabled); 1=Rx indication including Rx power up delay; 2=Rx High priority indicator; 3=NA
  [17:16] WLCTXPRIOMODE — Define BLE packet ble_tx mode behavior
    0=Tx indication excluding Tx power up delay; 1=Tx indication including Tx power up delay; 2=Tx High priority indicator; 3=NA
  [15:14] MWSTXFREQMSK — Determine how MWS Tx Frequency impacts BLE Tx and Rx
    0=mws Tx Frequency has no impact; 1=mws Tx Frequency can stop BLE Tx, no impact on BLE Rx; 2=mws Tx Frequency can stop BLE Rx, no impact on BLE Tx; 3=mws Tx Frequency can stop both BLE Tx and BLE Rx
  [13:12] MWSRXFREQMSK — Determine how MWS Rx frequency impacts BLE Tx and Rx
    values as MWSTXFREQMSK
  [11:10] MWSTXMSK — Determine how mws_tx impacts BLE Tx and Rx
    0=mws_tx has no impact; 1=mws_tx can stop BLE Tx, no impact on BLE Rx; 2=mws_tx can stop BLE Rx, no impact on BLE Tx; 3=mws_tx can stop both BLE Tx and BLE Rx
  [9:8] MWSRXMSK — Determine how mws_rx impacts BLE Tx and Rx
    values as MWSTXMSK
  [7:6] WLANTXMSK — Determine how wlan_tx impacts BLE Tx and Rx
    0=wlan_tx has no impact; 1=wlan_tx can stop BLE Tx, no impact on BLE Rx; 2=wlan_tx can stop BLE Rx, no impact on BLE Tx; 3=wlan_tx can stop both BLE Tx and BLE Rx
  [5:4] WLANRXMSK — Determine how wlan_rx impacts BLE Tx and Rx
    0=wlan_rx has no impact; 1=wlan_rx can stop BLE Tx, no impact on BLE Rx; 2=wlan_rx can stop BLE Rx, no impact on BLE Tx; 3=wlan_rx can stop both BLE Tx and BLE Rx
  [3] MWSWCI_EN — Enable/disable control of the WCI MWS coexistence interface (valid in dual mode only)
    0=MWS WCI Interface disabled; 1=MWS WCI Interface enabled
  [2] MWSCOEX_EN — Enable/disable control of the MWS Coexistence control (valid in dual mode only)
    0=MWS Coexistence interface disabled; 1=MWS Coexistence interface enabled
  [1] SYNCGEN_EN — Determine whether ble_sync is generated or not
    0=ble_sync pulse not generated; 1=ble_sync pulse generated
  [0] WLANCOEX_EN — Enable/disable control of the MWS/WLAN coexistence control
    0=COEX_EN_0 (Coexistence interface disabled); 1=COEX_EN_1 (Coexistence interface enabled)
0x144 BB_COEXIFCNTL1 — WLAN coexistence control register 1
  [28:24] WLCPRXTHR — Determine the threshold for Rx priority setting (apply on ble_rx if WLCRXPRIOMODE equals "10")
    0=If ble_pti[3:0] output value is greater than WLCPRXTHR, then Rx BLE priority is considered as high, and must be provided to the WLAN coexistence interface
  [20:16] WLCPTXTHR — Determine the threshold for priority setting (apply on ble_tx if WLCTXPRIOMODE equals "10")
    0=If ble_pti[3:0] output value is greater than WLCPTXTHR, then Tx BLE priority is considered as high, and must be provided to the WLAN coexistence interface
  [14:8] WLCPDURATION — Determine how many us the priority information must be maintained (apply on ble_tx and ble_rx if WLCTXPRIOMODE and WLCRXPRIOMODE equal "10")
    0=Note that if WLCPDURATION = 0x00, then Tx/Rx priority levels are maintained till Tx/Rx EN are de-asserted
  [6:0] WLCPDELAY — Determine the delay (in us) in Tx/Rx enables rises the time BLE Tx/Rx priority has to be provided (apply on ble_tx and ble_rx if WLCTXPRIOMODE and WLCRXPRIOMODE equal "10")
0x148 BB_COEXIFCNTL2 — WLAN coexistence control register 2
  [11:8] RX_ANT_DELAY — Time (in us) by which is anticipated bt_rx to be provided before effective radio receipt operation
  [3:0] TX_ANT_DELAY — Time (in us) by which is anticipated bt_tx to be provided before effective radio transmit operation
0x14C BB_BLEMPRIO0 reset 0x3489ADEF — Priority control register 0
  [31:28] BLEM7 — Set priority value for passive scanning
    3=BLEM7_3
  [27:24] BLEM6 — Set priority value for non-connectable advertising
    4=BLEM6_4
  [23:20] BLEM5 — Set priority value for connectable advertising BLE message
    8=BLEM5_8
  [19:16] BLEM4 — Set priority value for active scanning BLE message
    9=BLEM4_9
  [15:12] BLEM3 — Set priority value for initiating (scanning) BLE message
    10=BLEM3_10
  [11:8] BLEM2 — Set priority value for data channel transmission BLE message
    13=BLEM2_13
  [7:4] BLEM1 — Set priority value for LLCP BLE message
    14=BLEM1_14
  [3:0] BLEM0 — Set priority value for initiating (connection request response) BLE message
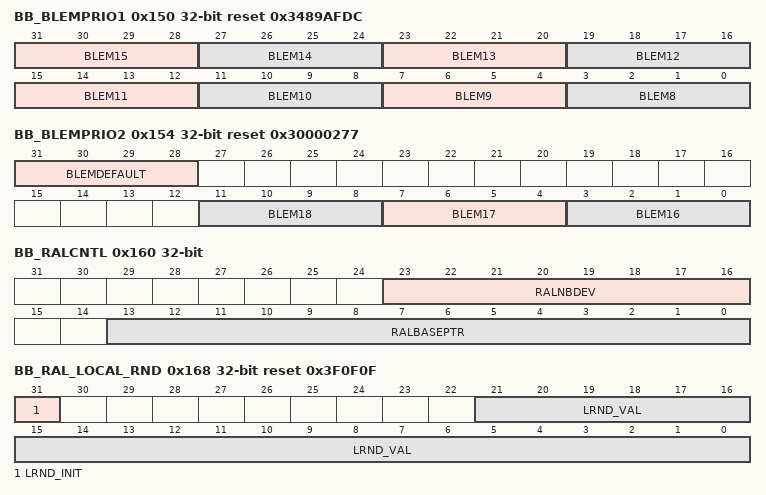
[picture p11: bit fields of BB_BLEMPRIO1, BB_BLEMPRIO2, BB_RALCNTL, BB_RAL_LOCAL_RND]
0x150 BB_BLEMPRIO1 reset 0x3489AFDC — Priority control register 1
  [31:28] BLEM15 — Set priority value for passive extended passive scanning on secondary advertising channels
    3=BLEM15_3
  [27:24] BLEM14 — Set priority value for non-connectable extended advertising on secondary advertising channels
    4=BLEM14_4
  [23:20] BLEM13 — Set priority value for connectable extended advertising on secondary advertising channels
    8=BLEM13_8
  [19:16] BLEM12 — Set priority value for extended active scanning on secondary advertising channels
    9=BLEM12_9
  [15:12] BLEM11 — Set priority value for extended initiating on secondary advertising channels
    10=BLEM11_10
  [11:8] BLEM10 — Set priority value for connection establishment BLE message on secondary advertising channels
    15=BLEM10_15
  [7:4] BLEM9 — Set default priority value for ISO channel subsequent Tx/Rx attempt
    13=BLEM9_13
  [3:0] BLEM8 — Set default priority value for ISO channel first Tx/Rx attempt
    12=BLEM8_12
0x154 BB_BLEMPRIO2 reset 0x30000277 — Priority control register 2
  [31:28] BLEMDEFAULT — Set priority value for extended initiating on secondary advertising channels
  [11:8] BLEM18 — Set priority value for connection establishment BLE message on secondary advertising channels
    2=BLEM18_2
  [7:4] BLEM17 — Set default priority value for ISO channel subsequent Tx/Rx attempt
    7=BLEM17_7
  [3:0] BLEM16 — Set default priority value for ISO channel first Tx/Rx attempt
    7=BLEM16_7
0x160 BB_RALCNTL — Control of the Resolving Address List engine
  [23:16] RALNBDEV — Number of devices in RAL structure
  [13:0] RALBASEPTR — Start address pointer of the RAL structure
0x164 BB_RALCURRENTPTR — Current pointer of the RAL structure
  [13:0] RALCURRENTPTR
0x168 BB_RAL_LOCAL_RND reset 0x3F0F0F — Register used by the local Resolving Address List engine
  [31] LRND_INIT — Writing a 1 initializes of local RPA random number generation LFSR
  [21:0] LRND_VAL — Initialization value for local RPA random generation when LRDN_INIT is set to 1 (report the current local RPA random number LFSR value otherwise)
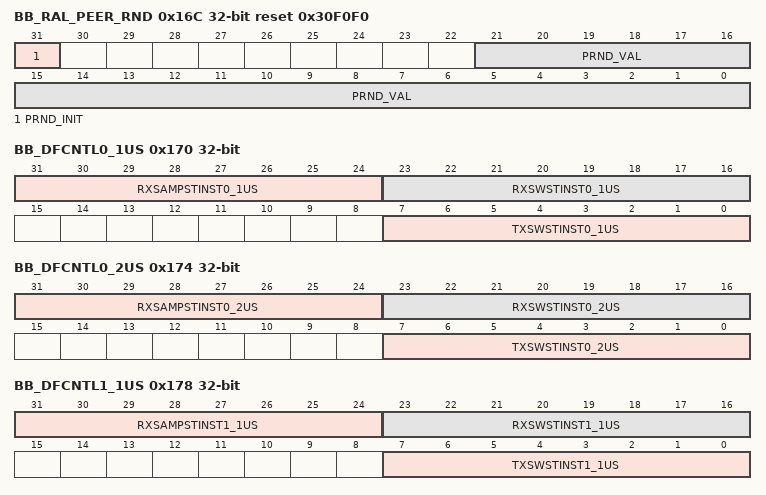
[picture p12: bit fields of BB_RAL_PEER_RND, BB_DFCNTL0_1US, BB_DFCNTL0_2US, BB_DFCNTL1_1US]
0x16C BB_RAL_PEER_RND reset 0x30F0F0 — Register used by the peer Resolving Address List engine
  [31] PRND_INIT — Writing a 1 initializes of peer RPA random number generation LFSR
  [21:0] PRND_VAL — Initialization value for peer RPA random generation when LRDN_INIT is set to 1 (report the current local RPA random number LFSR value otherwise)
0x170 BB_DFCNTL0_1US — AoA/AOD control register 0 (1us)
  [31:24] RXSAMPSTINST0_1US — Adjustement delay in half us of Rx I&Q sampling start instant for LE 1M PHY (with 1us sampling interval)
    0=RXSAMPSTINST0_1US_0
  [23:16] RXSWSTINST0_1US — Adjustement delay in half us of Rx switch start instant for LE 1M PHY (with 1us switching interval)
    0=RXSWSTINST0_1US_0
  [7:0] TXSWSTINST0_1US — Adjustement delay in half us of Tx switch start instant for LE 1M PHY (with 1us switching interval)
    0=TXSWSTINST0_1US_0
0x174 BB_DFCNTL0_2US — AoA/AOD control register 0 (2us)
  [31:24] RXSAMPSTINST0_2US — Adjustement delay in half us of Rx I&Q sampling start instant for LE 1M PHY (with 2us sampling interval)
    0=RXSAMPSTINST0_2US_0
  [23:16] RXSWSTINST0_2US — Adjustement delay in half us of Rx switch start instant for LE 1M PHY (with 2us switching interval)
    0=RXSWSTINST0_2US_0
  [7:0] TXSWSTINST0_2US — Adjustement delay in half us of Tx switch start instant for LE 1M PHY (with 2us switching interval)
    0=TXSWSTINST0_2US_0
0x178 BB_DFCNTL1_1US — AoA/AOD control register 1 (1us)
  [31:24] RXSAMPSTINST1_1US — Adjustement delay in half us of Rx I&Q sampling start instant for LE 2M PHY (with 1us sampling interval)
    0=RXSAMPSTINST1_1US_0
  [23:16] RXSWSTINST1_1US — Adjustement delay in half us of Rx switch start instant for LE 2M PHY (with 1us switching interval)
    0=RXSWSTINST1_1US_0
  [7:0] TXSWSTINST1_1US — Adjustement delay in half us of Tx switch start instant for LE 2M PHY (with 1us switching interval)
    0=TXSWSTINST1_1US_0
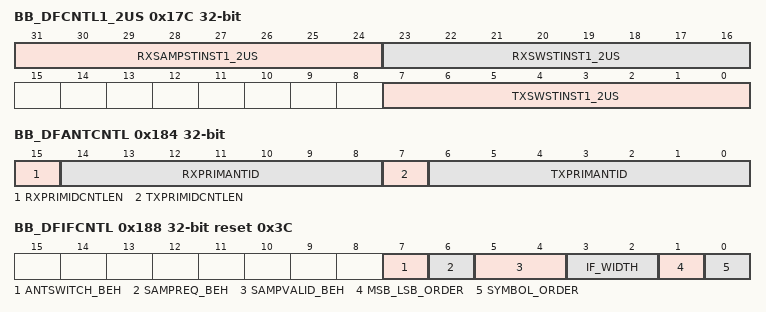
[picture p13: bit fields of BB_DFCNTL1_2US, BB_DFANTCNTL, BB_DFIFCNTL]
0x17C BB_DFCNTL1_2US — AoA/AOD control register 1 (2us)
  [31:24] RXSAMPSTINST1_2US — Adjustement delay in half us of Rx I&Q sampling start instant for LE 2M PHY (with 2us sampling interval)
    0=RXSAMPSTINST1_2US_0
  [23:16] RXSWSTINST1_2US — Adjustement delay in half us of Rx switch start instant for LE 2M PHY (with 2us switching interval)
    0=RXSWSTINST1_2US_0
  [7:0] TXSWSTINST1_2US — Adjustement delay in half us of Tx switch start instant for LE 2M PHY (with 2us switching interval)
    0=TXSWSTINST1_2US_0
0x180 BB_DFCURRENTPTR — Rx CTE descriptor current pointer
  [13:0] DFCURRENTPTR
0x184 BB_DFANTCNTL — AoA/AOD antenna control register
  [15] RXPRIMIDCNTLEN — Reception primary antenna ID enable control
    0=RXPRIMANTID not used on each Rx start; 1=RXPRIMANTID used on each Rx start
  [14:8] RXPRIMANTID — Primary antenna ID to be used on each Rx start instant
  [7] TXPRIMIDCNTLEN — Transmit primary antenna ID enable control
    0=TXPRIMANTID not used on each Tx start; 1=TXPRIMANTID used on each Tx start
  [6:0] TXPRIMANTID — Primary antenna ID to be used on each Tx start instant
0x188 BB_DFIFCNTL reset 0x3C — AoA/AOD interface control register
  [7] ANTSWITCH_BEH — Define the antenna switch qualifier behavior
    0=radio_out[28] is a pulse; 1=radio_out[28] is a toggle
  [6] SAMPREQ_BEH — Define the I&Q sampling request behavior
    0=radio_out[29] is a pulse; 1=radio_out[29] is a toggle
  [5:4] SAMPVALID_BEH — Define the I&Q sample qualifier behavior
    0=I&Q sample aligned on radio_in[33] rising edges; 1=I&Q sample aligned on radio_in[33] falling edges; 2=I&Q sample aligned on radio_in[33] edges (toggle mode); 3=NA
  [3:2] IF_WIDTH — Define the I&Q sample interface width
    0=NA; 1=4-bit interface; 2=8-bit interface; 3=16-bit interface
  [1] MSB_LSB_ORDER — Define whether symbol is sent MSB or LSB first
    0=MSB sent first; 1=LSB sent first
  [0] SYMBOL_ORDER — Define whether I sample or Q sample is sent first
    0=I sample is sent first; 1=Q sample is sent first
